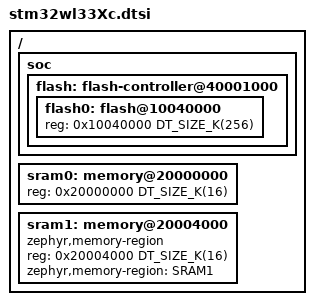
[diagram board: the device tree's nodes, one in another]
/*
 * Copyright (c) 2024 STMicroelectronics
 * Copyright (c) 2026 Movu robotics
 *
 * SPDX-License-Identifier: Apache-2.0
 */

#include <st/wl3/stm32wl33.dtsi>

/ {

	soc {
		flash: flash-controller@40001000 {
			flash0: flash@10040000 {
				reg = <0x10040000 DT_SIZE_K(256)>;
			};
		};
	};

	sram0: memory@20000000 {
		reg = <0x20000000 DT_SIZE_K(16)>;
	};

	sram1: memory@20004000 {
		reg = <0x20004000 DT_SIZE_K(16)>;
		compatible = "zephyr,memory-region", "mmio-sram";
		zephyr,memory-region = "SRAM1";
	};

};

